AUTOSAR XML (schema 4-0-3)
package /ComponentTypes
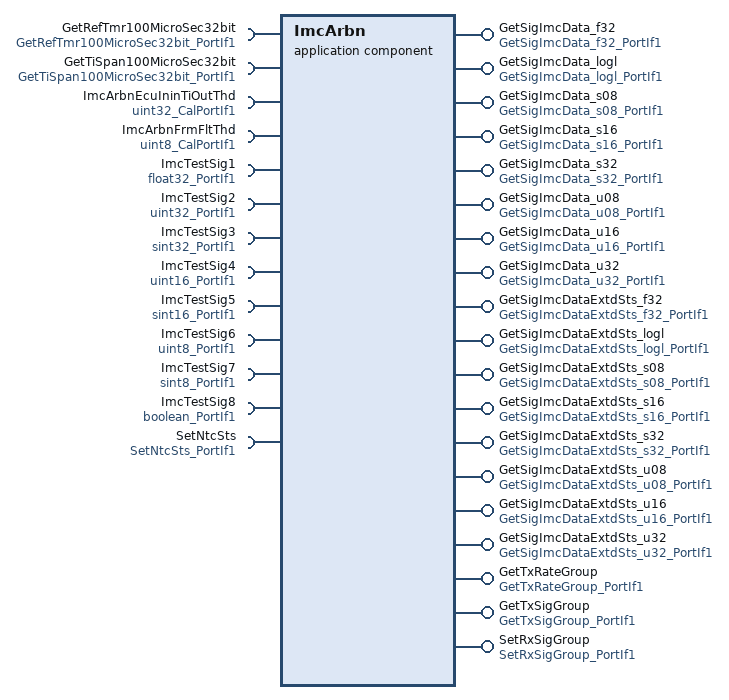
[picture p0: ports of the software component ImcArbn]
  application sw component type ImcArbn
    19 x provide port, all with server-com-spec{operation=Oper, queue-length=1}:
      GetSigImcData_f32: provided-interface=GetSigImcData_f32_PortIf1
      GetSigImcData_logl: provided-interface=GetSigImcData_logl_PortIf1
      GetSigImcData_s08: provided-interface=GetSigImcData_s08_PortIf1
      GetSigImcData_s16: provided-interface=GetSigImcData_s16_PortIf1
      GetSigImcData_s32: provided-interface=GetSigImcData_s32_PortIf1
      GetSigImcData_u08: provided-interface=GetSigImcData_u08_PortIf1
      GetSigImcData_u16: provided-interface=GetSigImcData_u16_PortIf1
      GetSigImcData_u32: provided-interface=GetSigImcData_u32_PortIf1
      GetSigImcDataExtdSts_f32: provided-interface=GetSigImcDataExtdSts_f32_PortIf1
      GetSigImcDataExtdSts_logl: provided-interface=GetSigImcDataExtdSts_logl_PortIf1
      GetSigImcDataExtdSts_s08: provided-interface=GetSigImcDataExtdSts_s08_PortIf1
      GetSigImcDataExtdSts_s16: provided-interface=GetSigImcDataExtdSts_s16_PortIf1
      GetSigImcDataExtdSts_s32: provided-interface=GetSigImcDataExtdSts_s32_PortIf1
      GetSigImcDataExtdSts_u08: provided-interface=GetSigImcDataExtdSts_u08_PortIf1
      GetSigImcDataExtdSts_u16: provided-interface=GetSigImcDataExtdSts_u16_PortIf1
      GetSigImcDataExtdSts_u32: provided-interface=GetSigImcDataExtdSts_u32_PortIf1
      GetTxRateGroup: provided-interface=GetTxRateGroup_PortIf1
      GetTxSigGroup: provided-interface=GetTxSigGroup_PortIf1
      SetRxSigGroup: provided-interface=SetRxSigGroup_PortIf1
    13 x require port:
      GetRefTmr100MicroSec32bit: required-interface=GetRefTmr100MicroSec32bit_PortIf1
      GetTiSpan100MicroSec32bit: required-interface=GetTiSpan100MicroSec32bit_PortIf1
      ImcArbnEcuIninTiOutThd: parameter-require-com-spec{init-value=500, parameter=Val}, required-interface=uint32_CalPortIf1
      ImcArbnFrmFltThd: parameter-require-com-spec{init-value=10, parameter=Val}, required-interface=uint8_CalPortIf1
      ImcTestSig1: nonqueued-receiver-com-spec{data-element=Val, filter=data-filter-type=ALWAYS, init-value=0}, required-interface=float32_PortIf1
      ImcTestSig2: nonqueued-receiver-com-spec{data-element=Val, filter=data-filter-type=ALWAYS, init-value=0}, required-interface=uint32_PortIf1
      ImcTestSig3: nonqueued-receiver-com-spec{data-element=Val, filter=data-filter-type=ALWAYS, init-value=0}, required-interface=sint32_PortIf1
      ImcTestSig4: nonqueued-receiver-com-spec{data-element=Val, filter=data-filter-type=ALWAYS, init-value=0}, required-interface=uint16_PortIf1
      ImcTestSig5: nonqueued-receiver-com-spec{data-element=Val, filter=data-filter-type=ALWAYS, init-value=0}, required-interface=sint16_PortIf1
      ImcTestSig6: nonqueued-receiver-com-spec{data-element=Val, filter=data-filter-type=ALWAYS, init-value=0}, required-interface=uint8_PortIf1
      ImcTestSig7: nonqueued-receiver-com-spec{data-element=Val, filter=data-filter-type=ALWAYS, init-value=0}, required-interface=sint8_PortIf1
      ImcTestSig8: nonqueued-receiver-com-spec{data-element=Logl, filter=data-filter-type=ALWAYS, init-value=0}, required-interface=boolean_PortIf1
      SetNtcSts: required-interface=SetNtcSts_PortIf1
    behavior ImcArbn_InternalBehavior
      exclusive area ExclsvAr1DrvrTxRxBuf
      exclusive area ExclsvAr2SigDataBuf
      ar-typed-per-instance-memorys:
        22 x data, all with sw-calibration-access=READ-ONLY:
          FrmFltCntr100MilliSec: type=Ary2D_u8_2_2
          FrmFltCntr10MilliSec: type=Ary2D_u8_2_2
          FrmFltCntr2MilliSec: type=Ary2D_u8_2_2
          ImcEcuComStrtTiRef: type=uint32
          PrevRollgCntrRxd: type=Ary1D_u8_ImcArbnB
          PrimSrcResyncCntr: type=Ary1D_u8_ImcArbnB
          PrimSrcRollgCntrResync: type=Ary1D_u8_ImcArbnB
          PrimSrcRxBuf: type=Ary2D_u8_ImcArbnA
          ResyncOnPrimActv: type=Ary1D_logl_ImcArbnA
          ResyncOnSecdryActv: type=Ary1D_logl_ImcArbnA
          RollgCntr: type=Ary1D_u8_3
          RxdSigData: type=Ary1D_u32_ImcArbnA
          RxdSigDataExtdSts: type=Ary1D_ImrArbnRxExtdSts2_ImcArbnA
          RxdSigDataSrc: type=Ary1D_ImcArbnRxDataSrc2_ImcArbnA
          SecdrySrcResyncCntr: type=Ary1D_u8_ImcArbnB
          SecdrySrcRollgCntrResync: type=Ary1D_u8_ImcArbnB
          SecdrySrcRxBuf: type=Ary2D_u8_ImcArbnA
          SigGroupDataSrc: type=Ary1D_ImcArbnRxDataSrc2_ImcArbnB
          SigGroupMissCntr: type=Ary1D_u8_ImcArbnB
          SigGroupNeverRxd: type=Ary1D_logl_ImcArbnA
          SigGroupSkipCntr: type=Ary1D_u8_ImcArbnB
          TxBuf: type=Ary2D_u8_ImcArbnA
      18 x operation invoked event:
        OIT_GetSigImcData_f32_Oper_GetSigImcData_f32_Oper: start-on-event=GetSigImcData_f32_Oper, operation=GetSigImcData_f32.Oper
        OIT_GetSigImcData_logl_Oper_GetSigImcData_logl_Oper: start-on-event=GetSigImcData_logl_Oper, operation=GetSigImcData_logl.Oper
        OIT_GetSigImcData_s08_Oper_GetSigImcData_s08_Oper: start-on-event=GetSigImcData_s08_Oper, operation=GetSigImcData_s08.Oper
        OIT_GetSigImcData_s16_Oper_GetSigImcData_s16_Oper: start-on-event=GetSigImcData_s16_Oper, operation=GetSigImcData_s16.Oper
        OIT_GetSigImcData_s32_Oper_GetSigImcData_s32_Oper: start-on-event=GetSigImcData_s32_Oper, operation=GetSigImcData_s32.Oper
        OIT_GetSigImcData_u08_Oper_GetSigImcData_u08_Oper: start-on-event=GetSigImcData_u08_Oper, operation=GetSigImcData_u08.Oper
        OIT_GetSigImcData_u16_Oper_GetSigImcData_u16_Oper: start-on-event=GetSigImcData_u16_Oper, operation=GetSigImcData_u16.Oper
        OIT_GetSigImcData_u32_Oper_GetSigImcData_u32_Oper: start-on-event=GetSigImcData_u32_Oper, operation=GetSigImcData_u32.Oper
        OIT_GetSigImcDataExtdSts_f32_Oper_GetSigImcDataExtdSts_f32_Oper: start-on-event=GetSigImcDataExtdSts_f32_Oper, operation=GetSigImcDataExtdSts_f32.Oper
        OIT_GetSigImcDataExtdSts_logl_Oper_GetSigImcDataExtdSts_logl_Oper: start-on-event=GetSigImcDataExtdSts_logl_Oper, operation=GetSigImcDataExtdSts_logl.Oper
        OIT_GetSigImcDataExtdSts_s08_Oper_GetSigImcDataExtdSts_s08_Oper: start-on-event=GetSigImcDataExtdSts_s08_Oper, operation=GetSigImcDataExtdSts_s08.Oper
        OIT_GetSigImcDataExtdSts_s16_Oper_GetSigImcDataExtdSts_s16_Oper: start-on-event=GetSigImcDataExtdSts_s16_Oper, operation=GetSigImcDataExtdSts_s16.Oper
        OIT_GetSigImcDataExtdSts_s32_Oper_GetSigImcDataExtdSts_s32_Oper: start-on-event=GetSigImcDataExtdSts_s32_Oper, operation=GetSigImcDataExtdSts_s32.Oper
        OIT_GetSigImcDataExtdSts_u08_Oper_GetSigImcDataExtdSts_u08_Oper: start-on-event=GetSigImcDataExtdSts_u08_Oper, operation=GetSigImcDataExtdSts_u08.Oper
        OIT_GetSigImcDataExtdSts_u16_Oper_GetSigImcDataExtdSts_u16_Oper: start-on-event=GetSigImcDataExtdSts_u16_Oper, operation=GetSigImcDataExtdSts_u16.Oper
        OIT_GetSigImcDataExtdSts_u32_Oper_GetSigImcDataExtdSts_u32_Oper: start-on-event=GetSigImcDataExtdSts_u32_Oper, operation=GetSigImcDataExtdSts_u32.Oper
        OIT_GetTxRateGroup_Oper_GetTxRateGroup_Oper: start-on-event=GetTxRateGroup_Oper, operation=GetTxRateGroup.Oper
        OIT_GetTxSigGroup_Oper_GetTxSigGroup_Oper: start-on-event=GetTxSigGroup_Oper, operation=GetTxSigGroup.Oper
      7 x timing event:
        ImcArbn_InitEvent: start-on-event=ImcArbnInit1, period=0
        TMT_ImcArbrPer1: start-on-event=ImcArbnPer1, period=0.002
        TMT_ImcArbrPer2: start-on-event=ImcArbnPer2, period=0.01
        TMT_ImcArbrPer3: start-on-event=ImcArbnPer3, period=0.1
        TMT_ImcArbrPer4: start-on-event=ImcArbnPer4, period=0.002
        TMT_ImcArbrPer5: start-on-event=ImcArbnPer5, period=0.01
        TMT_ImcArbrPer6: start-on-event=ImcArbnPer6, period=0.1
      operation invoked event OIT_SetRxSigGroup_Oper_SetRxSigGroup_Oper: start-on-event=SetRxSigGroup_Oper, operation=SetRxSigGroup.Oper
      explicit-inter-runnable-variables:
        data IniTiOutChkCmpl: type=boolean, init-value=0
      26 x runnable:
        GetSigImcData_f32_Oper: can-enter-exclusive-area=ExclsvAr2SigDataBuf, can-be-invoked-concurrently=true
        GetSigImcData_logl_Oper: can-enter-exclusive-area=ExclsvAr2SigDataBuf, can-be-invoked-concurrently=true
        GetSigImcData_s08_Oper: can-enter-exclusive-area=ExclsvAr2SigDataBuf, can-be-invoked-concurrently=true
        GetSigImcData_s16_Oper: can-enter-exclusive-area=ExclsvAr2SigDataBuf, can-be-invoked-concurrently=true
        GetSigImcData_s32_Oper: can-enter-exclusive-area=ExclsvAr2SigDataBuf, can-be-invoked-concurrently=true
        GetSigImcData_u08_Oper: can-enter-exclusive-area=ExclsvAr2SigDataBuf, can-be-invoked-concurrently=true
        GetSigImcData_u16_Oper: can-enter-exclusive-area=ExclsvAr2SigDataBuf, can-be-invoked-concurrently=true
        GetSigImcData_u32_Oper: can-enter-exclusive-area=ExclsvAr2SigDataBuf, can-be-invoked-concurrently=true
        GetSigImcDataExtdSts_f32_Oper: can-enter-exclusive-area=ExclsvAr2SigDataBuf, can-be-invoked-concurrently=true
        GetSigImcDataExtdSts_logl_Oper: can-enter-exclusive-area=ExclsvAr2SigDataBuf, can-be-invoked-concurrently=true
        GetSigImcDataExtdSts_s08_Oper: can-enter-exclusive-area=ExclsvAr2SigDataBuf, can-be-invoked-concurrently=true
        GetSigImcDataExtdSts_s16_Oper: can-enter-exclusive-area=ExclsvAr2SigDataBuf, can-be-invoked-concurrently=true
        GetSigImcDataExtdSts_s32_Oper: can-enter-exclusive-area=ExclsvAr2SigDataBuf, can-be-invoked-concurrently=true
        GetSigImcDataExtdSts_u08_Oper: can-enter-exclusive-area=ExclsvAr2SigDataBuf, can-be-invoked-concurrently=true
        GetSigImcDataExtdSts_u16_Oper: can-enter-exclusive-area=ExclsvAr2SigDataBuf, can-be-invoked-concurrently=true
        GetSigImcDataExtdSts_u32_Oper: can-enter-exclusive-area=ExclsvAr2SigDataBuf, can-be-invoked-concurrently=true
        GetTxRateGroup_Oper: can-enter-exclusive-area=ExclsvAr1DrvrTxRxBuf, can-be-invoked-concurrently=true
        GetTxSigGroup_Oper: can-enter-exclusive-area=ExclsvAr1DrvrTxRxBuf, can-be-invoked-concurrently=true
        ImcArbnInit1
          sync call SC_GetRefTmr100MicroSec32bit_Oper: operation=GetRefTmr100MicroSec32bit.Oper, timeout=0
        ImcArbnPer1: can-enter-exclusive-area=ExclsvAr1DrvrTxRxBuf
          data-receive-point-by-arguments:
            6 x access:
              REC_ImcTestSig1_Val: accessed-variable=ImcTestSig1.Val
              REC_ImcTestSig{4..7}_Val: accessed-variable=ImcTestSig{4..7}.Val
              REC_ImcTestSig8_Logl: accessed-variable=ImcTestSig8.Logl
        ImcArbnPer2: can-enter-exclusive-area=ExclsvAr1DrvrTxRxBuf
          data-receive-point-by-arguments:
            access REC_ImcTestSig2_Val: accessed-variable=ImcTestSig2.Val
        ImcArbnPer3: can-enter-exclusive-area=ExclsvAr1DrvrTxRxBuf
          data-receive-point-by-arguments:
            access REC_ImcTestSig3_Val: accessed-variable=ImcTestSig3.Val
        ImcArbnPer4: can-enter-exclusive-area=[ExclsvAr1DrvrTxRxBuf, ExclsvAr2SigDataBuf]
          read-local-variables:
            access READ_IniTiOutChkCmpl: accessed-variable=IniTiOutChkCmpl
        ImcArbnPer5: can-enter-exclusive-area=[ExclsvAr1DrvrTxRxBuf, ExclsvAr2SigDataBuf]
          read-local-variables:
            access READ_IniTiOutChkCmpl: accessed-variable=IniTiOutChkCmpl
        ImcArbnPer6: can-enter-exclusive-area=[ExclsvAr1DrvrTxRxBuf, ExclsvAr2SigDataBuf]
          read-local-variables:
            access READ_IniTiOutChkCmpl: accessed-variable=IniTiOutChkCmpl
          sync call SC_GetRefTmr100MicroSec32bit_Oper: operation=GetRefTmr100MicroSec32bit.Oper, timeout=0
          sync call SC_GetTiSpan100MicroSec32bit_Oper: operation=GetTiSpan100MicroSec32bit.Oper, timeout=0
          sync call SC_SetNtcSts_Oper: operation=SetNtcSts.Oper, timeout=0
          written-local-variables:
            access WRITE_IniTiOutChkCmpl: accessed-variable=IniTiOutChkCmpl
        SetRxSigGroup_Oper: can-enter-exclusive-area=ExclsvAr1DrvrTxRxBuf
  swc implementation ImcArbn_Implementation: behavior=ImcArbn_InternalBehavior
    code-descriptors:
      code Default: artifact-descriptors=autosar-engineering-object={short-label=Default, category=SWSRC}
